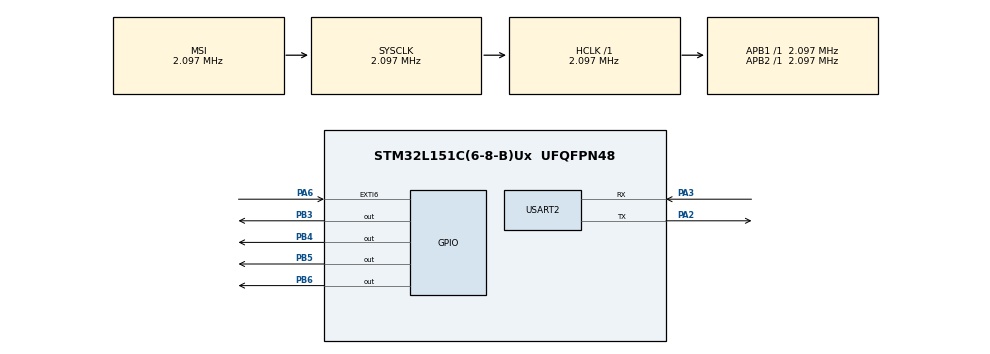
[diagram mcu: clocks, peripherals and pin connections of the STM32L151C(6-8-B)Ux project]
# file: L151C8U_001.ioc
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Mcu.Family=STM32L1
Mcu.Name=STM32L151C(6-8-B)Ux
Mcu.Package=UFQFPN48
NVIC.EXTI9_5_IRQn=true\:6\:0\:true\:false\:true\:true
NVIC.PriorityGroup=NVIC_PRIORITYGROUP_4
NVIC.RCC_IRQn=true\:0\:0\:false\:false\:true\:true
NVIC.RTC_WKUP_IRQn=true\:0\:0\:false\:false\:true\:true
PA0-WKUP1.Mode=SYS_WakeUp0
PA0-WKUP1.Signal=SYS_WKUP1
PA2.Mode=Asynchronous
PA2.Signal=USART2_TX
PA3.Mode=Asynchronous
PA3.Signal=USART2_RX
PA6.GPIO_ModeDefaultEXTI=GPIO_MODE_IT_FALLING
PA6.Signal=GPXTI6
PB3.GPIO_PuPd=GPIO_PULLUP
PB3.GPIO_Speed=GPIO_SPEED_FREQ_VERY_HIGH
PB3.Signal=GPIO_Output
PB4.GPIO_PuPd=GPIO_PULLUP
PB4.GPIO_Speed=GPIO_SPEED_FREQ_VERY_HIGH
PB4.Signal=GPIO_Output
PB5.GPIO_PuPd=GPIO_PULLUP
PB5.GPIO_Speed=GPIO_SPEED_FREQ_VERY_HIGH
PB5.Signal=GPIO_Output
PB6.GPIO_PuPd=GPIO_PULLUP
PB6.GPIO_Speed=GPIO_SPEED_FREQ_VERY_HIGH
PB6.Signal=GPIO_Output
PC14-OSC32_IN.Mode=LSE-External-Oscillator
PC14-OSC32_IN.Signal=RCC_OSC32_IN
PC15-OSC32_OUT.Mode=LSE-External-Oscillator
PC15-OSC32_OUT.Signal=RCC_OSC32_OUT
PH0-OSC_IN.Mode=HSE-External-Oscillator
PH0-OSC_IN.Signal=RCC_OSC_IN
PH1-OSC_OUT.Mode=HSE-External-Oscillator
PH1-OSC_OUT.Signal=RCC_OSC_OUT
ProjectManager.HeapSize=0x200
ProjectManager.StackSize=0x400
ProjectManager.TargetToolchain=TrueSTUDIO
RCC.AHBFreq_Value=2097000
RCC.APB1Freq_Value=2097000
RCC.APB2Freq_Value=2097000
RCC.HSE_VALUE=24000000
RCC.HSI_VALUE=16000000
RCC.MSI_VALUE=2097000
RCC.SYSCLKFreq_VALUE=2097000
RCC.VCOOutputFreq_Value=48000000
RTC.WakeUpClock-WakeUp=RTC_WAKEUPCLOCK_CK_SPRE_16BITS
RTC.WakeUpCounter-WakeUp=59
USART2.VirtualMode=VM_ASYNC
VP_RTC_VS_RTC_Activate.Mode=RTC_Enabled
VP_RTC_VS_RTC_Calendar.Mode=RTC_Calendar
VP_RTC_VS_RTC_WakeUp_intern.Mode=WakeUp
board=custom

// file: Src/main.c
/**
  ******************************************************************************
  * @file           : main.c
  * @brief          : Main program body
  ******************************************************************************
  ** This notice applies to any and all portions of this file
  * that are not between comment pairs USER CODE BEGIN and
  * USER CODE END. Other portions of this file, whether
  * inserted by the user or by software development tools
  * are owned by their respective copyright owners.
  *
  * COPYRIGHT(c) 2018 STMicroelectronics
  *
  * Redistribution and use in source and binary forms, with or without modification,
  * are permitted provided that the following conditions are met:
  *   1. Redistributions of source code must retain the above copyright notice,
  *      this list of conditions and the following disclaimer.
  *   2. Redistributions in binary form must reproduce the above copyright notice,
  *      this list of conditions and the following disclaimer in the documentation
  *      and/or other materials provided with the distribution.
  *   3. Neither the name of STMicroelectronics nor the names of its contributors
  *      may be used to endorse or promote products derived from this software
  *      without specific prior written permission.
  *
  * THIS SOFTWARE IS PROVIDED BY THE COPYRIGHT HOLDERS AND CONTRIBUTORS "AS IS"
  * AND ANY EXPRESS OR IMPLIED WARRANTIES, INCLUDING, BUT NOT LIMITED TO, THE
  * IMPLIED WARRANTIES OF MERCHANTABILITY AND FITNESS FOR A PARTICULAR PURPOSE ARE
  * DISCLAIMED. IN NO EVENT SHALL THE COPYRIGHT HOLDER OR CONTRIBUTORS BE LIABLE
  * FOR ANY DIRECT, INDIRECT, INCIDENTAL, SPECIAL, EXEMPLARY, OR CONSEQUENTIAL
  * DAMAGES (INCLUDING, BUT NOT LIMITED TO, PROCUREMENT OF SUBSTITUTE GOODS OR
  * SERVICES; LOSS OF USE, DATA, OR PROFITS; OR BUSINESS INTERRUPTION) HOWEVER
  * CAUSED AND ON ANY THEORY OF LIABILITY, WHETHER IN CONTRACT, STRICT LIABILITY,
  * OR TORT (INCLUDING NEGLIGENCE OR OTHERWISE) ARISING IN ANY WAY OUT OF THE USE
  * OF THIS SOFTWARE, EVEN IF ADVISED OF THE POSSIBILITY OF SUCH DAMAGE.
  *
  ******************************************************************************
  */
#include "main.h"
#include "stm32l1xx_hal.h"

RTC_HandleTypeDef hrtc;

UART_HandleTypeDef huart2;

/* USER CODE BEGIN PV */
/* Private variables ---------------------------------------------------------*/

/* USER CODE END PV */

void SystemClock_Config(void);
static void MX_GPIO_Init(void);
static void MX_USART2_UART_Init(void);
static void MX_RTC_Init(void);

/* USER CODE BEGIN PFP */
/* Private function prototypes -----------------------------------------------*/

/* USER CODE END PFP */

int main(void)
{

  /* MCU Configuration----------------------------------------------------------*/

  /* Reset of all peripherals, Initializes the Flash interface and the Systick. */
  HAL_Init();

  /* Configure the system clock */
  SystemClock_Config();

  /* USER CODE BEGIN SysInit */
  MX_USART2_UART_Init();
  /* USER CODE END SysInit */

  /* Initialize all configured peripherals */
  MX_GPIO_Init();
  MX_RTC_Init();

  /* Infinite loop */
  while (1)
  {

  }

}

void SystemClock_Config(void)
{

  RCC_OscInitTypeDef RCC_OscInitStruct;
  RCC_ClkInitTypeDef RCC_ClkInitStruct;
  RCC_PeriphCLKInitTypeDef PeriphClkInit;

    /**Configure the main internal regulator output voltage
    */
  __HAL_PWR_VOLTAGESCALING_CONFIG(PWR_REGULATOR_VOLTAGE_SCALE1);

    /**Initializes the CPU, AHB and APB busses clocks
    */
  RCC_OscInitStruct.OscillatorType = RCC_OSCILLATORTYPE_LSI|RCC_OSCILLATORTYPE_MSI;
  RCC_OscInitStruct.LSIState = RCC_LSI_ON;
  RCC_OscInitStruct.MSIState = RCC_MSI_ON;
  RCC_OscInitStruct.MSICalibrationValue = 0;
  RCC_OscInitStruct.MSIClockRange = RCC_MSIRANGE_5;
  RCC_OscInitStruct.PLL.PLLState = RCC_PLL_NONE;
  if (HAL_RCC_OscConfig(&RCC_OscInitStruct) != HAL_OK)
  {
    _Error_Handler(__FILE__, __LINE__);
  }

    /**Initializes the CPU, AHB and APB busses clocks
    */
  RCC_ClkInitStruct.ClockType = RCC_CLOCKTYPE_HCLK|RCC_CLOCKTYPE_SYSCLK
                              |RCC_CLOCKTYPE_PCLK1|RCC_CLOCKTYPE_PCLK2;
  RCC_ClkInitStruct.SYSCLKSource = RCC_SYSCLKSOURCE_MSI;
  RCC_ClkInitStruct.AHBCLKDivider = RCC_SYSCLK_DIV1;
  RCC_ClkInitStruct.APB1CLKDivider = RCC_HCLK_DIV1;
  RCC_ClkInitStruct.APB2CLKDivider = RCC_HCLK_DIV1;

  if (HAL_RCC_ClockConfig(&RCC_ClkInitStruct, FLASH_LATENCY_0) != HAL_OK)
  {
    _Error_Handler(__FILE__, __LINE__);
  }

  PeriphClkInit.PeriphClockSelection = RCC_PERIPHCLK_RTC;
  PeriphClkInit.RTCClockSelection = RCC_RTCCLKSOURCE_LSI;
  if (HAL_RCCEx_PeriphCLKConfig(&PeriphClkInit) != HAL_OK)
  {
    _Error_Handler(__FILE__, __LINE__);
  }

    /**Configure the Systick interrupt time
    */
  HAL_SYSTICK_Config(HAL_RCC_GetHCLKFreq()/1000);

    /**Configure the Systick
    */
  HAL_SYSTICK_CLKSourceConfig(SYSTICK_CLKSOURCE_HCLK);

  /* SysTick_IRQn interrupt configuration */
  HAL_NVIC_SetPriority(SysTick_IRQn, 0, 0);
}

/* RTC init function */
static void MX_RTC_Init(void)
{

  RTC_TimeTypeDef sTime;
  RTC_DateTypeDef sDate;

    /**Initialize RTC Only
    */
  hrtc.Instance = RTC;
  hrtc.Init.HourFormat = RTC_HOURFORMAT_24;
  hrtc.Init.AsynchPrediv = 127;
  hrtc.Init.SynchPrediv = 255;
  hrtc.Init.OutPut = RTC_OUTPUT_DISABLE;
  hrtc.Init.OutPutPolarity = RTC_OUTPUT_POLARITY_HIGH;
  hrtc.Init.OutPutType = RTC_OUTPUT_TYPE_OPENDRAIN;
  if (HAL_RTC_Init(&hrtc) != HAL_OK)
  {
    _Error_Handler(__FILE__, __LINE__);
  }

    /**Initialize RTC and set the Time and Date
    */
  sTime.Hours = 0x0;
  sTime.Minutes = 0x0;
  sTime.Seconds = 0x0;
  sTime.DayLightSaving = RTC_DAYLIGHTSAVING_NONE;
  sTime.StoreOperation = RTC_STOREOPERATION_RESET;
  if (HAL_RTC_SetTime(&hrtc, &sTime, RTC_FORMAT_BCD) != HAL_OK)
  {
    _Error_Handler(__FILE__, __LINE__);
  }

  sDate.WeekDay = RTC_WEEKDAY_MONDAY;
  sDate.Month = RTC_MONTH_JANUARY;
  sDate.Date = 0x1;
  sDate.Year = 0x0;

  if (HAL_RTC_SetDate(&hrtc, &sDate, RTC_FORMAT_BCD) != HAL_OK)
  {
    _Error_Handler(__FILE__, __LINE__);
  }

    /**Enable the WakeUp
    */
  if (HAL_RTCEx_SetWakeUpTimer_IT(&hrtc, 59, RTC_WAKEUPCLOCK_CK_SPRE_16BITS) != HAL_OK)
  {
    _Error_Handler(__FILE__, __LINE__);
  }

}

/* USART2 init function */
static void MX_USART2_UART_Init(void)
{

  huart2.Instance = USART2;
  huart2.Init.BaudRate = 115200;
  huart2.Init.WordLength = UART_WORDLENGTH_8B;
  huart2.Init.StopBits = UART_STOPBITS_1;
  huart2.Init.Parity = UART_PARITY_NONE;
  huart2.Init.Mode = UART_MODE_TX_RX;
  huart2.Init.HwFlowCtl = UART_HWCONTROL_NONE;
  huart2.Init.OverSampling = UART_OVERSAMPLING_16;
  if (HAL_UART_Init(&huart2) != HAL_OK)
  {
    _Error_Handler(__FILE__, __LINE__);
  }

}

/** Configure pins as
        * Analog
        * Input
        * Output
        * EVENT_OUT
        * EXTI
*/
static void MX_GPIO_Init(void)
{

  GPIO_InitTypeDef GPIO_InitStruct;

  /* GPIO Ports Clock Enable */
  __HAL_RCC_GPIOC_CLK_ENABLE();
  __HAL_RCC_GPIOH_CLK_ENABLE();
  __HAL_RCC_GPIOA_CLK_ENABLE();
  __HAL_RCC_GPIOB_CLK_ENABLE();

  /*Configure GPIO pin Output Level */
  HAL_GPIO_WritePin(GPIOB, GPIO_PIN_3|GPIO_PIN_4|GPIO_PIN_5|GPIO_PIN_6, GPIO_PIN_RESET);

  /*Configure GPIO pin : PA6 */
  GPIO_InitStruct.Pin = GPIO_PIN_6;
  GPIO_InitStruct.Mode = GPIO_MODE_IT_FALLING;
  GPIO_InitStruct.Pull = GPIO_NOPULL;
  HAL_GPIO_Init(GPIOA, &GPIO_InitStruct);

  /*Configure GPIO pins : PB3 PB4 PB5 PB6 */
  GPIO_InitStruct.Pin = GPIO_PIN_3|GPIO_PIN_4|GPIO_PIN_5|GPIO_PIN_6;
  GPIO_InitStruct.Mode = GPIO_MODE_OUTPUT_PP;
  GPIO_InitStruct.Pull = GPIO_PULLUP;
  GPIO_InitStruct.Speed = GPIO_SPEED_FREQ_VERY_HIGH;
  HAL_GPIO_Init(GPIOB, &GPIO_InitStruct);

  /* EXTI interrupt init*/
  HAL_NVIC_SetPriority(EXTI9_5_IRQn, 6, 0);
  HAL_NVIC_EnableIRQ(EXTI9_5_IRQn);

}

void _Error_Handler(char *file, int line)
{
  while(1)
  {
  }
}

/************************ (C) COPYRIGHT STMicroelectronics *****END OF FILE****/
